AUTOSAR XML (schema 4-0-3)
package /ComponentTypes
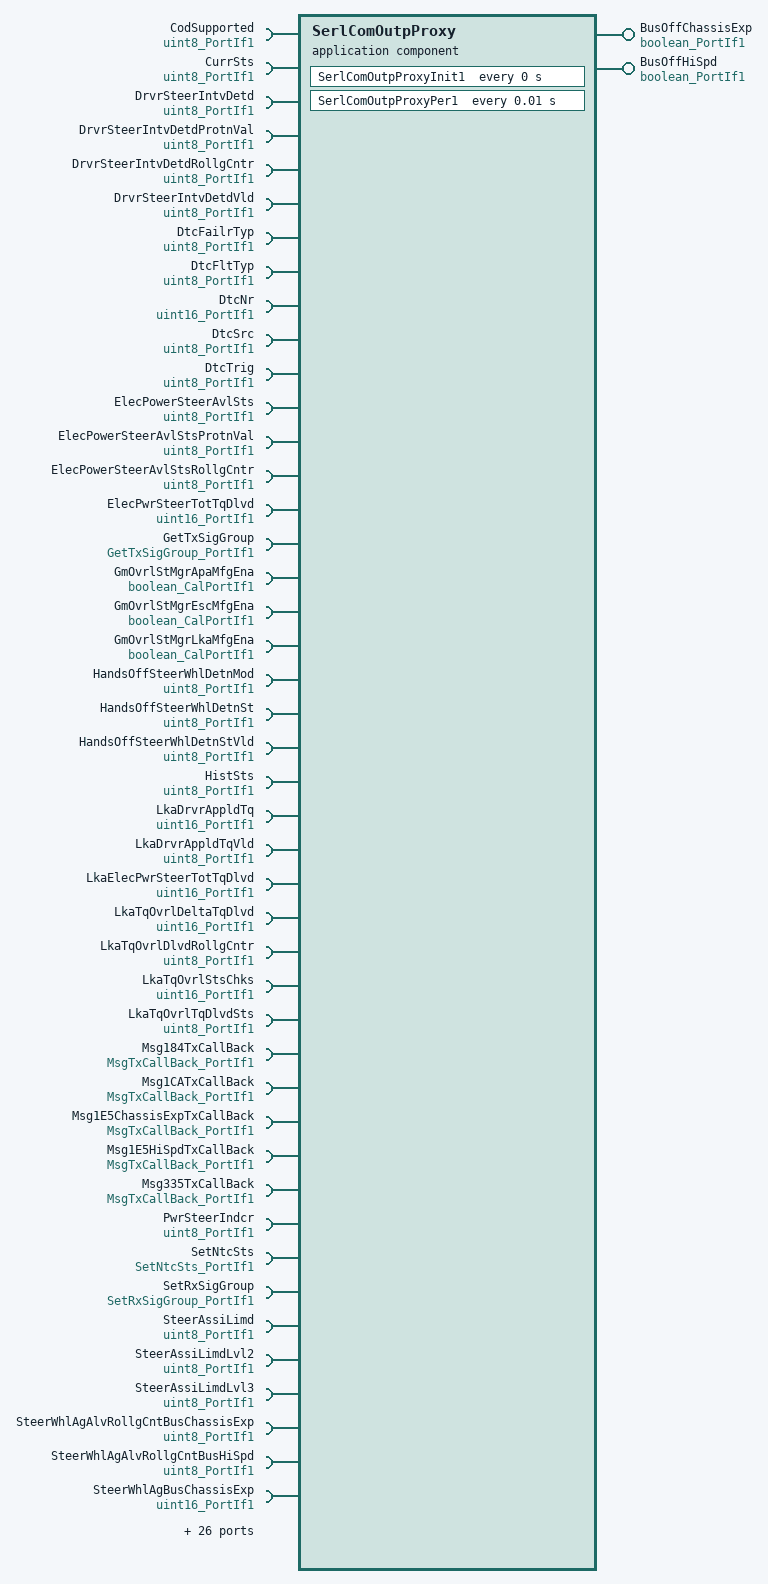
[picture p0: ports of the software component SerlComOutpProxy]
  application sw component type SerlComOutpProxy
    provide port BusOffChassisExp: nonqueued-sender-com-spec{data-element=Logl, init-value=0}, provided-interface=boolean_PortIf1
    provide port BusOffHiSpd: nonqueued-sender-com-spec{data-element=Logl, init-value=0}, provided-interface=boolean_PortIf1
    70 x require port:
      CodSupported: nonqueued-receiver-com-spec{data-element=Val, filter=data-filter-type=ALWAYS, init-value=0}, required-interface=uint8_PortIf1
      CurrSts: nonqueued-receiver-com-spec{data-element=Val, filter=data-filter-type=ALWAYS, init-value=0}, required-interface=uint8_PortIf1
      DrvrSteerIntvDetd: nonqueued-receiver-com-spec{data-element=Val, filter=data-filter-type=ALWAYS, init-value=0}, required-interface=uint8_PortIf1
      DrvrSteerIntvDetdProtnVal: nonqueued-receiver-com-spec{data-element=Val, filter=data-filter-type=ALWAYS, init-value=0}, required-interface=uint8_PortIf1
      DrvrSteerIntvDetdRollgCntr: nonqueued-receiver-com-spec{data-element=Val, filter=data-filter-type=ALWAYS, init-value=0}, required-interface=uint8_PortIf1
      DrvrSteerIntvDetdVld: nonqueued-receiver-com-spec{data-element=Val, filter=data-filter-type=ALWAYS, init-value=0}, required-interface=uint8_PortIf1
      DtcFailrTyp: nonqueued-receiver-com-spec{data-element=Val, filter=data-filter-type=ALWAYS, init-value=0}, required-interface=uint8_PortIf1
      DtcFltTyp: nonqueued-receiver-com-spec{data-element=Val, filter=data-filter-type=ALWAYS, init-value=0}, required-interface=uint8_PortIf1
      DtcNr: nonqueued-receiver-com-spec{data-element=Val, filter=data-filter-type=ALWAYS, init-value=0}, required-interface=uint16_PortIf1
      DtcSrc: nonqueued-receiver-com-spec{data-element=Val, filter=data-filter-type=ALWAYS, init-value=0}, required-interface=uint8_PortIf1
      DtcTrig: nonqueued-receiver-com-spec{data-element=Val, filter=data-filter-type=ALWAYS, init-value=0}, required-interface=uint8_PortIf1
      ElecPowerSteerAvlSts: nonqueued-receiver-com-spec{data-element=Val, filter=data-filter-type=ALWAYS, init-value=0}, required-interface=uint8_PortIf1
      ElecPowerSteerAvlStsProtnVal: nonqueued-receiver-com-spec{data-element=Val, filter=data-filter-type=ALWAYS, init-value=0}, required-interface=uint8_PortIf1
      ElecPowerSteerAvlStsRollgCntr: nonqueued-receiver-com-spec{data-element=Val, filter=data-filter-type=ALWAYS, init-value=0}, required-interface=uint8_PortIf1
      ElecPwrSteerTotTqDlvd: nonqueued-receiver-com-spec{data-element=Val, filter=data-filter-type=ALWAYS, init-value=0}, required-interface=uint16_PortIf1
      GetTxSigGroup: required-interface=GetTxSigGroup_PortIf1
      GmOvrlStMgrApaMfgEna: parameter-require-com-spec{init-value=0, parameter=Logl}, required-interface=boolean_CalPortIf1
      GmOvrlStMgrEscMfgEna: parameter-require-com-spec{init-value=0, parameter=Logl}, required-interface=boolean_CalPortIf1
      GmOvrlStMgrLkaMfgEna: parameter-require-com-spec{init-value=0, parameter=Logl}, required-interface=boolean_CalPortIf1
      HandsOffSteerWhlDetnMod: nonqueued-receiver-com-spec{data-element=Val, filter=data-filter-type=ALWAYS, init-value=0}, required-interface=uint8_PortIf1
      HandsOffSteerWhlDetnSt: nonqueued-receiver-com-spec{data-element=Val, filter=data-filter-type=ALWAYS, init-value=0}, required-interface=uint8_PortIf1
      HandsOffSteerWhlDetnStVld: nonqueued-receiver-com-spec{data-element=Val, filter=data-filter-type=ALWAYS, init-value=0}, required-interface=uint8_PortIf1
      HistSts: nonqueued-receiver-com-spec{data-element=Val, filter=data-filter-type=ALWAYS, init-value=0}, required-interface=uint8_PortIf1
      LkaDrvrAppldTq: nonqueued-receiver-com-spec{data-element=Val, filter=data-filter-type=ALWAYS, init-value=0}, required-interface=uint16_PortIf1
      LkaDrvrAppldTqVld: nonqueued-receiver-com-spec{data-element=Val, filter=data-filter-type=ALWAYS, init-value=0}, required-interface=uint8_PortIf1
      LkaElecPwrSteerTotTqDlvd: nonqueued-receiver-com-spec{data-element=Val, filter=data-filter-type=ALWAYS, init-value=0}, required-interface=uint16_PortIf1
      LkaTqOvrlDeltaTqDlvd: nonqueued-receiver-com-spec{data-element=Val, filter=data-filter-type=ALWAYS, init-value=0}, required-interface=uint16_PortIf1
      LkaTqOvrlDlvdRollgCntr: nonqueued-receiver-com-spec{data-element=Val, filter=data-filter-type=ALWAYS, init-value=0}, required-interface=uint8_PortIf1
      LkaTqOvrlStsChks: nonqueued-receiver-com-spec{data-element=Val, filter=data-filter-type=ALWAYS, init-value=0}, required-interface=uint16_PortIf1
      LkaTqOvrlTqDlvdSts: nonqueued-receiver-com-spec{data-element=Val, filter=data-filter-type=ALWAYS, init-value=0}, required-interface=uint8_PortIf1
      Msg184TxCallBack: required-interface=MsgTxCallBack_PortIf1
      Msg1CATxCallBack: required-interface=MsgTxCallBack_PortIf1
      Msg1E5ChassisExpTxCallBack: required-interface=MsgTxCallBack_PortIf1
      Msg1E5HiSpdTxCallBack: required-interface=MsgTxCallBack_PortIf1
      Msg335TxCallBack: required-interface=MsgTxCallBack_PortIf1
      PwrSteerIndcr: nonqueued-receiver-com-spec{data-element=Val, filter=data-filter-type=ALWAYS, init-value=0}, required-interface=uint8_PortIf1
      SetNtcSts: required-interface=SetNtcSts_PortIf1
      SetRxSigGroup: required-interface=SetRxSigGroup_PortIf1
      SteerAssiLimd: nonqueued-receiver-com-spec{data-element=Val, filter=data-filter-type=ALWAYS, init-value=0}, required-interface=uint8_PortIf1
      SteerAssiLimdLvl2: nonqueued-receiver-com-spec{data-element=Val, filter=data-filter-type=ALWAYS, init-value=0}, required-interface=uint8_PortIf1
      SteerAssiLimdLvl3: nonqueued-receiver-com-spec{data-element=Val, filter=data-filter-type=ALWAYS, init-value=0}, required-interface=uint8_PortIf1
      SteerWhlAgAlvRollgCntBusChassisExp: nonqueued-receiver-com-spec{data-element=Val, filter=data-filter-type=ALWAYS, init-value=0}, required-interface=uint8_PortIf1
      SteerWhlAgAlvRollgCntBusHiSpd: nonqueued-receiver-com-spec{data-element=Val, filter=data-filter-type=ALWAYS, init-value=0}, required-interface=uint8_PortIf1
      SteerWhlAgBusChassisExp: nonqueued-receiver-com-spec{data-element=Val, filter=data-filter-type=ALWAYS, init-value=0}, required-interface=uint16_PortIf1
      SteerWhlAgBusHiSpd: nonqueued-receiver-com-spec{data-element=Val, filter=data-filter-type=ALWAYS, init-value=0}, required-interface=uint16_PortIf1
      SteerWhlAgGrdtBusChassisExp: nonqueued-receiver-com-spec{data-element=Val, filter=data-filter-type=ALWAYS, init-value=0}, required-interface=uint16_PortIf1
      SteerWhlAgGrdtBusHiSpd: nonqueued-receiver-com-spec{data-element=Val, filter=data-filter-type=ALWAYS, init-value=0}, required-interface=uint16_PortIf1
      SteerWhlAgGrdtMaskBusChassisExp: nonqueued-receiver-com-spec{data-element=Val, filter=data-filter-type=ALWAYS, init-value=0}, required-interface=uint8_PortIf1
      SteerWhlAgGrdtMaskBusHiSpd: nonqueued-receiver-com-spec{data-element=Val, filter=data-filter-type=ALWAYS, init-value=0}, required-interface=uint8_PortIf1
      SteerWhlAgGrdtVldBusChassisExp: nonqueued-receiver-com-spec{data-element=Val, filter=data-filter-type=ALWAYS, init-value=0}, required-interface=uint8_PortIf1
      SteerWhlAgGrdtVldBusHiSpd: nonqueued-receiver-com-spec{data-element=Val, filter=data-filter-type=ALWAYS, init-value=0}, required-interface=uint8_PortIf1
      SteerWhlAgMaskBusChassisExp: nonqueued-receiver-com-spec{data-element=Val, filter=data-filter-type=ALWAYS, init-value=0}, required-interface=uint8_PortIf1
      SteerWhlAgMaskBusHiSpd: nonqueued-receiver-com-spec{data-element=Val, filter=data-filter-type=ALWAYS, init-value=0}, required-interface=uint8_PortIf1
      SteerWhlAgSnsrCalStsBusChassisExp: nonqueued-receiver-com-spec{data-element=Val, filter=data-filter-type=ALWAYS, init-value=0}, required-interface=uint8_PortIf1
      SteerWhlAgSnsrCalStsBusHiSpd: nonqueued-receiver-com-spec{data-element=Val, filter=data-filter-type=ALWAYS, init-value=0}, required-interface=uint8_PortIf1
      SteerWhlAgSnsrChksBusChassisExp: nonqueued-receiver-com-spec{data-element=Val, filter=data-filter-type=ALWAYS, init-value=0}, required-interface=uint16_PortIf1
      SteerWhlAgSnsrChksBusHiSpd: nonqueued-receiver-com-spec{data-element=Val, filter=data-filter-type=ALWAYS, init-value=0}, required-interface=uint16_PortIf1
      SteerWhlAgSnsrTypBusChassisExp: nonqueued-receiver-com-spec{data-element=Val, filter=data-filter-type=ALWAYS, init-value=0}, required-interface=uint8_PortIf1
      SteerWhlAgSnsrTypBusHiSpd: nonqueued-receiver-com-spec{data-element=Val, filter=data-filter-type=ALWAYS, init-value=0}, required-interface=uint8_PortIf1
      SteerWhlAgVldBusChassisExp: nonqueued-receiver-com-spec{data-element=Val, filter=data-filter-type=ALWAYS, init-value=0}, required-interface=uint8_PortIf1
      SteerWhlAgVldBusHiSpd: nonqueued-receiver-com-spec{data-element=Val, filter=data-filter-type=ALWAYS, init-value=0}, required-interface=uint8_PortIf1
      TqOvrlDeltaTqDlvd: nonqueued-receiver-com-spec{data-element=Val, filter=data-filter-type=ALWAYS, init-value=0}, required-interface=uint16_PortIf1
      TqOvrlDlvdChks: nonqueued-receiver-com-spec{data-element=Val, filter=data-filter-type=ALWAYS, init-value=0}, required-interface=uint16_PortIf1
      TqOvrlDlvdRollgCntr: nonqueued-receiver-com-spec{data-element=Val, filter=data-filter-type=ALWAYS, init-value=0}, required-interface=uint8_PortIf1
      TqOvrlTqDlvdSts: nonqueued-receiver-com-spec{data-element=Val, filter=data-filter-type=ALWAYS, init-value=0}, required-interface=uint8_PortIf1
      TstFaildCodClrdSts: nonqueued-receiver-com-spec{data-element=Val, filter=data-filter-type=ALWAYS, init-value=0}, required-interface=uint8_PortIf1
      TstFaildPwrUpSts: nonqueued-receiver-com-spec{data-element=Val, filter=data-filter-type=ALWAYS, init-value=0}, required-interface=uint8_PortIf1
      TstNotPassdCodClrdSts: nonqueued-receiver-com-spec{data-element=Val, filter=data-filter-type=ALWAYS, init-value=0}, required-interface=uint8_PortIf1
      TstNotPassdPwrUpSts: nonqueued-receiver-com-spec{data-element=Val, filter=data-filter-type=ALWAYS, init-value=0}, required-interface=uint8_PortIf1
      WarnIndcrReqdSts: nonqueued-receiver-com-spec{data-element=Val, filter=data-filter-type=ALWAYS, init-value=0}, required-interface=uint8_PortIf1
    behavior SerlComOutpProxy_InternalBehavior
      ar-typed-per-instance-memorys:
        data BusOffChassisExp: sw-calibration-access=READ-ONLY, type=boolean
        data BusOffHiSpd: sw-calibration-access=READ-ONLY, type=boolean
      timing event SerlComOutpProxyInit1_InitEvent: start-on-event=SerlComOutpProxyInit1, period=0
      timing event TMT_SerlComOutpProxyPer1: start-on-event=SerlComOutpProxyPer1, period=0.01
      runnable SerlComOutpProxyInit1
        sync call SC_SetNtcSts_Oper: operation=SetNtcSts.Oper, timeout=0
      runnable SerlComOutpProxyPer1
        data-receive-point-by-arguments:
          59 x access:
            REC_CodSupported_Val: accessed-variable=CodSupported.Val
            REC_CurrSts_Val: accessed-variable=CurrSts.Val
            REC_DrvrSteerIntvDetd_Val: accessed-variable=DrvrSteerIntvDetd.Val
            REC_DrvrSteerIntvDetdProtnVal_Val: accessed-variable=DrvrSteerIntvDetdProtnVal.Val
            REC_DrvrSteerIntvDetdRollgCntr_Val: accessed-variable=DrvrSteerIntvDetdRollgCntr.Val
            REC_DrvrSteerIntvDetdVld_Val: accessed-variable=DrvrSteerIntvDetdVld.Val
            REC_DtcFailrTyp_Val: accessed-variable=DtcFailrTyp.Val
            REC_DtcFltTyp_Val: accessed-variable=DtcFltTyp.Val
            REC_DtcNr_Val: accessed-variable=DtcNr.Val
            REC_DtcSrc_Val: accessed-variable=DtcSrc.Val
            REC_DtcTrig_Val: accessed-variable=DtcTrig.Val
            REC_ElecPowerSteerAvlSts_Val: accessed-variable=ElecPowerSteerAvlSts.Val
            REC_ElecPowerSteerAvlStsProtnVal_Val: accessed-variable=ElecPowerSteerAvlStsProtnVal.Val
            REC_ElecPowerSteerAvlStsRollgCntr_Val: accessed-variable=ElecPowerSteerAvlStsRollgCntr.Val
            REC_ElecPwrSteerTotTqDlvd_Val: accessed-variable=ElecPwrSteerTotTqDlvd.Val
            REC_GM1E5CESteerWhlAg_Val: accessed-variable=SteerWhlAgBusChassisExp.Val
            REC_GM1E5CESteerWhlAgAlvRollgCnt_Val: accessed-variable=SteerWhlAgAlvRollgCntBusChassisExp.Val
            REC_GM1E5CESteerWhlAgGrdt_Val: accessed-variable=SteerWhlAgGrdtBusChassisExp.Val
            REC_GM1E5CESteerWhlAgGrdtMask_Val: accessed-variable=SteerWhlAgGrdtMaskBusChassisExp.Val
            REC_GM1E5CESteerWhlAgGrdtVld_Val: accessed-variable=SteerWhlAgGrdtVldBusChassisExp.Val
            REC_GM1E5CESteerWhlAgMask_Val: accessed-variable=SteerWhlAgMaskBusChassisExp.Val
            REC_GM1E5CESteerWhlAgSnsrCalSts_Val: accessed-variable=SteerWhlAgSnsrCalStsBusChassisExp.Val
            REC_GM1E5CESteerWhlAgSnsrChks_Val: accessed-variable=SteerWhlAgSnsrChksBusChassisExp.Val
            REC_GM1E5CESteerWhlAgSnsrTyp_Val: accessed-variable=SteerWhlAgSnsrTypBusChassisExp.Val
            REC_GM1E5CESteerWhlAgVld_Val: accessed-variable=SteerWhlAgVldBusChassisExp.Val
            REC_GM1E5HSSteerWhlAg_Val: accessed-variable=SteerWhlAgBusHiSpd.Val
            REC_GM1E5HSSteerWhlAgAlvRollgCnt_Val: accessed-variable=SteerWhlAgAlvRollgCntBusHiSpd.Val
            REC_GM1E5HSSteerWhlAgGrdt_Val: accessed-variable=SteerWhlAgGrdtBusHiSpd.Val
            REC_GM1E5HSSteerWhlAgGrdtMask_Val: accessed-variable=SteerWhlAgGrdtMaskBusHiSpd.Val
            REC_GM1E5HSSteerWhlAgGrdtVld_Val: accessed-variable=SteerWhlAgGrdtVldBusHiSpd.Val
            REC_GM1E5HSSteerWhlAgMask_Val: accessed-variable=SteerWhlAgMaskBusHiSpd.Val
            REC_GM1E5HSSteerWhlAgSnsrCalSts_Val: accessed-variable=SteerWhlAgSnsrCalStsBusHiSpd.Val
            REC_GM1E5HSSteerWhlAgSnsrChks_Val: accessed-variable=SteerWhlAgSnsrChksBusHiSpd.Val
            REC_GM1E5HSSteerWhlAgSnsrTyp_Val: accessed-variable=SteerWhlAgSnsrTypBusHiSpd.Val
            REC_GM1E5HSSteerWhlAgVld_Val: accessed-variable=SteerWhlAgVldBusHiSpd.Val
            REC_HandsOffSteerWhlDetnMod_Val: accessed-variable=HandsOffSteerWhlDetnMod.Val
            REC_HandsOffSteerWhlDetnSt_Val: accessed-variable=HandsOffSteerWhlDetnSt.Val
            REC_HandsOffSteerWhlDetnStVld_Val: accessed-variable=HandsOffSteerWhlDetnStVld.Val
            REC_HistSts_Val: accessed-variable=HistSts.Val
            REC_LkaDrvrAppldTq_Val: accessed-variable=LkaDrvrAppldTq.Val
            REC_LkaDrvrAppldTqVld_Val: accessed-variable=LkaDrvrAppldTqVld.Val
            REC_LkaElecPwrSteerTotTqDlvd_Val: accessed-variable=LkaElecPwrSteerTotTqDlvd.Val
            REC_LkaTqOvrlDeltaTqDlvd_Val: accessed-variable=LkaTqOvrlDeltaTqDlvd.Val
            REC_LkaTqOvrlDlvdRollgCntr_Val: accessed-variable=LkaTqOvrlDlvdRollgCntr.Val
            REC_LkaTqOvrlStsChks_Val: accessed-variable=LkaTqOvrlStsChks.Val
            REC_LkaTqOvrlTqDlvdSts_Val: accessed-variable=LkaTqOvrlTqDlvdSts.Val
            REC_PwrSteerIndcr_Val: accessed-variable=PwrSteerIndcr.Val
            REC_SteerAssiLimd_Val: accessed-variable=SteerAssiLimd.Val
            REC_SteerAssiLimdLvl2_Val: accessed-variable=SteerAssiLimdLvl2.Val
            REC_SteerAssiLimdLvl3_Val: accessed-variable=SteerAssiLimdLvl3.Val
            REC_TqOvrlDeltaTqDlvd_Val: accessed-variable=TqOvrlDeltaTqDlvd.Val
            REC_TqOvrlDlvdChks_Val: accessed-variable=TqOvrlDlvdChks.Val
            REC_TqOvrlDlvdRollgCntr_Val: accessed-variable=TqOvrlDlvdRollgCntr.Val
            REC_TqOvrlTqDlvdSts_Val: accessed-variable=TqOvrlTqDlvdSts.Val
            REC_TstFaildCodClrdSts_Val: accessed-variable=TstFaildCodClrdSts.Val
            REC_TstFaildPwrUpSts_Val: accessed-variable=TstFaildPwrUpSts.Val
            REC_TstNotPassdCodClrdSts_Val: accessed-variable=TstNotPassdCodClrdSts.Val
            REC_TstNotPassdPwrUpSts_Val: accessed-variable=TstNotPassdPwrUpSts.Val
            REC_WarnIndcrReqdSts_Val: accessed-variable=WarnIndcrReqdSts.Val
        data-send-points:
          access SEND_BusOffChassisExp_Logl: accessed-variable=BusOffChassisExp.Logl
          access SEND_BusOffHiSpd_Logl: accessed-variable=BusOffHiSpd.Logl
        8 x sync call, all with timeout=0:
          SC_GetTxSigGroup_Oper: operation=GetTxSigGroup.Oper
          SC_Msg184TxCallBack_Oper: operation=Msg184TxCallBack.Oper
          SC_Msg1CATxCallBack_Oper: operation=Msg1CATxCallBack.Oper
          SC_Msg1E5ChassisExpTxCallBack_Oper: operation=Msg1E5ChassisExpTxCallBack.Oper
          SC_Msg1E5HiSpdTxCallBack_Oper: operation=Msg1E5HiSpdTxCallBack.Oper
          SC_Msg335TxCallBack_Oper: operation=Msg335TxCallBack.Oper
          SC_SetNtcSts_Oper: operation=SetNtcSts.Oper
          SC_SetRxSigGroup_Oper: operation=SetRxSigGroup.Oper
  swc implementation SerlComOutpProxy_Implementation: behavior=SerlComOutpProxy_InternalBehavior
    code-descriptors:
      code Default: artifact-descriptors=autosar-engineering-object={short-label=Default, category=SWSRC}
